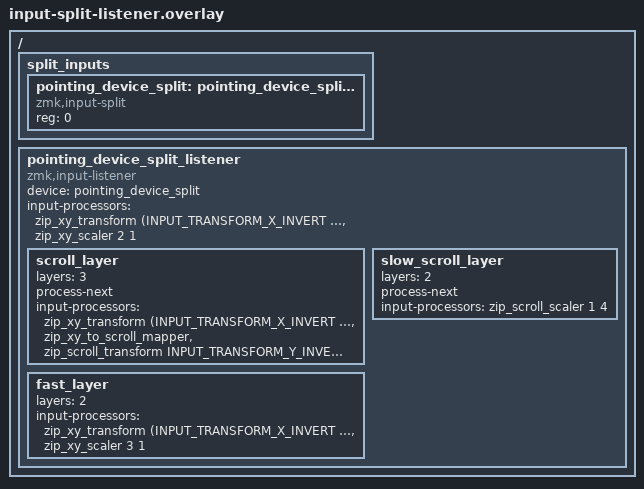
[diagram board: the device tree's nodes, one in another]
/{
    split_inputs {
        #address-cells = <1>;
        #size-cells = <0>;

        pointing_device_split: pointing_device_split@0 {
            compatible = "zmk,input-split";
            reg = <0>;
        };
    };

    pointing_device_split_listener: pointing_device_split_listener {
        compatible = "zmk,input-listener";
        device = <&pointing_device_split>;
        status = "okay";
        input-processors =
            <&zip_xy_transform (INPUT_TRANSFORM_X_INVERT | INPUT_TRANSFORM_Y_INVERT)>,
            <&zip_xy_scaler 2 1>;

        scroll_layer {
            layers = <3>;
            process-next;
            input-processors =
                <&zip_xy_transform (INPUT_TRANSFORM_X_INVERT | INPUT_TRANSFORM_Y_INVERT)>,
                <&zip_xy_to_scroll_mapper>,
                <&zip_scroll_transform INPUT_TRANSFORM_Y_INVERT>;
        };

        slow_scroll_layer {
            layers = <2>;
            process-next;
            input-processors =
                <&zip_scroll_scaler 1 4>;
        };

        fast_layer {
            layers = <2>;
            input-processors =
                <&zip_xy_transform (INPUT_TRANSFORM_X_INVERT | INPUT_TRANSFORM_Y_INVERT)>,
                <&zip_xy_scaler 3 1>;
        };
     };
};
